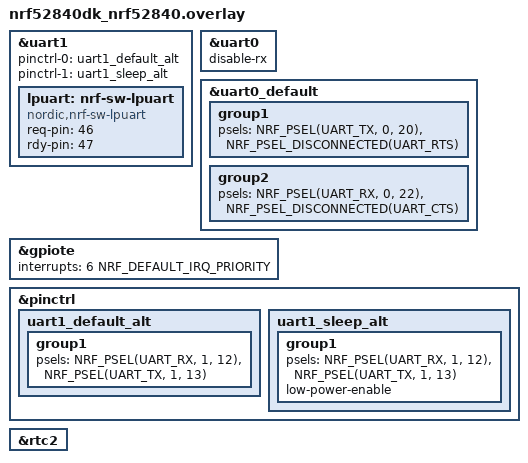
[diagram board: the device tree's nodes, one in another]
/* SPDX-License-Identifier: LicenseRef-Nordic-5-Clause */

&uart1 {
	status = "okay";
	pinctrl-0 = <&uart1_default_alt>;
	pinctrl-1 = <&uart1_sleep_alt>;
	pinctrl-names = "default", "sleep";
	lpuart: nrf-sw-lpuart {
		compatible = "nordic,nrf-sw-lpuart";
		status = "okay";
		req-pin = <46>;
		rdy-pin = <47>;
	};
};

&uart0 {
	disable-rx;
};

&uart0_default {
	/* Disconnect CTS and RTS lines from pins.
	 * This is a temporary workaround for increased current consumption
	 * observed on nRF52840 v3.0.0 only (~450 uA more then on v2.1.0).
	 */
	group1 {
		psels = <NRF_PSEL(UART_TX, 0, 20)>,
			<NRF_PSEL_DISCONNECTED(UART_RTS)>;
	};
	group2 {
		psels = <NRF_PSEL(UART_RX, 0, 22)>,
			<NRF_PSEL_DISCONNECTED(UART_CTS)>;
	};
};

&gpiote {
	interrupts = <6 NRF_DEFAULT_IRQ_PRIORITY>;
};

&pinctrl {
	uart1_default_alt: uart1_default_alt {
		group1 {
			psels = <NRF_PSEL(UART_RX, 1, 12)>,
				<NRF_PSEL(UART_TX, 1, 13)>;
		};
	};

	uart1_sleep_alt: uart1_sleep_alt {
		group1 {
			psels = <NRF_PSEL(UART_RX, 1, 12)>,
				<NRF_PSEL(UART_TX, 1, 13)>;
			low-power-enable;
		};
	};
};

&rtc2 {
	status = "okay";
};
